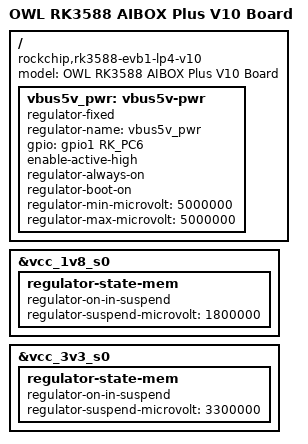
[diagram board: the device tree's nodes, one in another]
// SPDX-License-Identifier: (GPL-2.0+ OR MIT)
/*
 * Copyright (c) 2021 Rockchip Electronics Co., Ltd.
 *
 */

/dts-v1/;

#include "rk3588-evb1-lp4.dtsi"
#include "rk3588-evb1-imx415.dtsi"
#include "rk3588-linux.dtsi"

/ {
	model = "OWL RK3588 AIBOX Plus V10 Board";
	compatible = "rockchip,rk3588-evb1-lp4-v10", "rockchip,rk3588";

    vbus5v_pwr: vbus5v-pwr {
        compatible = "regulator-fixed";
        regulator-name = "vbus5v_pwr";
        gpio = <&gpio1 RK_PC6 GPIO_ACTIVE_HIGH>;
        enable-active-high;
        regulator-always-on;
        regulator-boot-on;
        regulator-min-microvolt = <5000000>;
        regulator-max-microvolt = <5000000>;
    };
};

&vcc_1v8_s0 {
	/delete-property/ regulator-state-mem;
	regulator-state-mem {
		regulator-on-in-suspend;
		regulator-suspend-microvolt = <1800000>;
	};
};

&vcc_3v3_s0 {
	/delete-property/ regulator-state-mem;
	regulator-state-mem {
		regulator-on-in-suspend;
		regulator-suspend-microvolt = <3300000>;
	};
};

